# TC37XPD register map
Vendor: Infineon; Series: ATVMC; File version: 100
CPU: other r0p0, little endian, MPU, FPU, vendor SysTick, 4 interrupt priority bits
Registers are 32-bit, read-write, reset 0x0 unless marked. A register's access mark holds for its fields unless they carry their own. Offsets are from the block's base; [hi:lo] are bit positions; lines under a group give offsets from that group; {n}, {i} and the like mark numbered series; 'fields as' and 'values as' point back to an identical list.

## GTM (part 13 of 13)
Base 0xF0100000
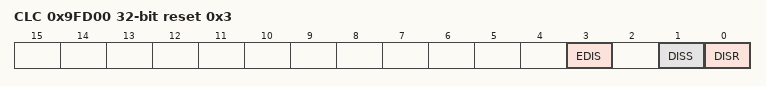
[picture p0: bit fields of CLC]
0x9FD00 CLC access per field reset 0x3 — Clock Control Register resetvalue={Application Reset:0x3}
  [3] EDIS rw — Sleep Mode Enable Control. Used for module s sleep mode control.
  [1] DISS ro — Module Disable Status Bit. This bit indicates the current status of the GTM module.
  [0] DISR rw — Module Disable Request Bit. Used for enable disable control of the GTM module.

## PMU
Base 0xF8038000
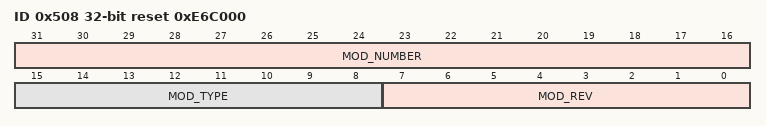
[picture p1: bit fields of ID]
0x508 ID ro reset 0xE6C000 (reset mask 0xFFFFFF00) — Module Identification Register resetvalue={Application Reset:0x0E6C000}
  [31:16] MOD_NUMBER — Module Number Value MOD NUMBER. This bit field defines the module identification number.
  [15:8] MOD_TYPE — Module Type MOD TYPE. This bit field is C0 H . It defines the module as a 32 bit module.
  [7:0] MOD_REV — Module Revision Number MOD REV. MOD REV defines the module revision number. See DMU Design Specification for MOD REV value.

## PFI0 — PFI
Base 0xA8080000
Same registers: PFI1 0xA8380000
0x00 ECCR ro — ECC Read Register resetvalue={System Reset:0x0}
  [21:0] RCODE — Error Correction Read Code RCODE. ECC code read from the Flash read buffer with last data read operation.
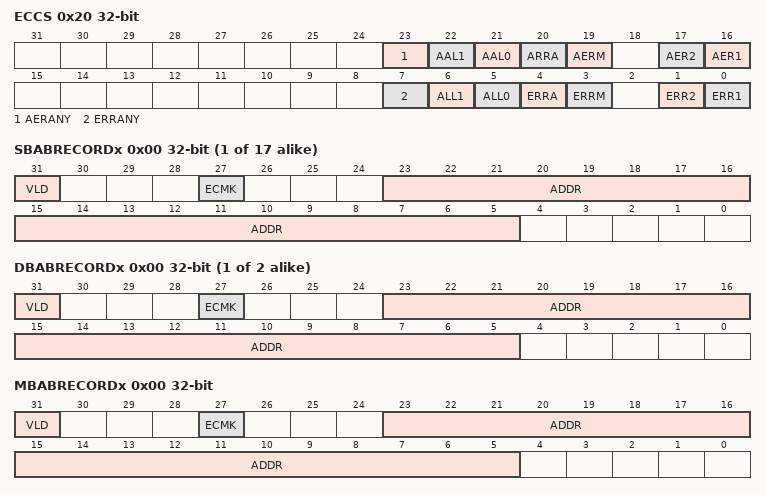
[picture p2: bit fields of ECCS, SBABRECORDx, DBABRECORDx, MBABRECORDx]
0x20 ECCS ro — ECC Status Register resetvalue={System Reset:0x0}
  [23] AERANY — Accumulated Any Read Access ECC Error AERANY. The status bit accumulates ECC failures during NVM read accesses.
  [22] AAL1 — Accumulated All Ones AAL1. The flag accumulates the All Ones condition during NVM read accesses.
  [21] AAL0 — Accumulated All Zeros AAL0. The flag accumulates the All Zeros condition during NVM read accesses.
  [20] ARRA — Accumulated ECC Error Within the Address ARRA. The flag accumulates an address errors during NVM read accesses.
  [19] AERM — Accumulated Multi bit ECC Errors AERM. The flag accumulates multi bit failures during NVM read accesses.
  [17] AER2 — Accumulated Double Bit ECC Errors AER2. The flag accumulates double bit failures during NVM read operations.
  [16] AER1 — Accumulated Single Bit ECC Errors AER1. The flag accumulates single bit failures during NVM read operations.
  [7] ERRANY — Any Read Access ECC Error ERRANY. The flag reports any ECC failure during the last NVM read access.
  [6] ALL1 — All Ones ALL1. The flag reports the All Ones condition during the last NVM read access.
  [5] ALL0 — Read Access All Zeros ALL0. The flag reports the All Zeros condition during the last NVM read access.
  [4] ERRA — Read Access ECC Error Within the Address ERRA. The flag reports an address error during the last NVM read access.
  [3] ERRM — Read Access Multi bit ECC Error ERRM. The flag reports multi bit ECC failure during the last NVM read access.
  [1] ERR2 — Read Access Double Bit ECC Error ERR2. The flag reports a double bit ECC failure during the last NVM read access.
  [0] ERR1 — Read Access Single Bit ECC Error ERR1. The flag reports a single bit ECC failure during the last NVM read access.
{0x2000+0x20*i} SBAB[{i}] (i=0..16) group
  0x00 SBABRECORDx ro — SBAB Record 0 resetvalue={System Reset:0x0}
    [31] VLD — Valid VLD
    [27] ECMK — Erase Counter Marker ECMK. The captured address is from the Flash or Erase Counter.
    [23:5] ADDR — Address ADDR. Captured local PFLASH bank address of the page with detected error.
{0x4000+0x20*i} DBAB[{i}] (i=0..1) group
  0x00 DBABRECORDx ro — DBAB Record 0 resetvalue={System Reset:0x0}
    [31] VLD — Valid VLD
    [27] ECMK — Erase Counter Marker ECMK. The captured address is from the Flash or Erase Counter.
    [23:5] ADDR — Address ADDR. Captured address of local PFLASH bank with detected error.
{0x8000+4i} MBAB[{i}] (i=0..0) group
  0x00 MBABRECORDx ro — MBAB Record 0 resetvalue={System Reset:0x0}
    fields as DBAB[0].DBABRECORDx
{0xC000+0x20*i} ZBAB[{i}] (i=0..3) group
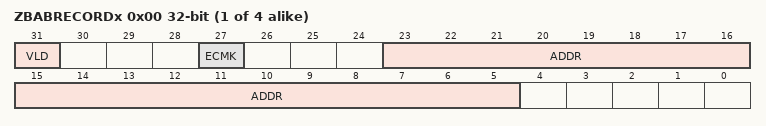
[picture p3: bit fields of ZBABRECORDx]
  0x00 ZBABRECORDx ro — ZBAB Record 0 resetvalue={System Reset:0x0}
    fields as DBAB[0].DBABRECORDx

## FSI
Base 0xF8030000
0x04 COMM_1 8-bit — Communication Register 1 resetvalue={System Reset:0x0}
  [7:0] COMM1 — FSI Communication 1 COMM1. This register can be written by FSI and DMU and is used to give status handshake information between FSI and DMU.
0x05 COMM_2 8-bit — Communication Register 2 resetvalue={System Reset:0x0}
  [7:0] COMM2 — FSI Communication 2 COMM2. This register can be written by FSI and DMU and is used to give status handshake information between FSI and DMU.
0x06 HSMCOMM_1 8-bit — HSM Communication Register 1 resetvalue={System Reset:0x0}
  [7:0] HSMCOMM1 — HSM FSI Communication 1 HSMCOMM1. This register can be written by FSI and DMU and is used to give status handshake information between FSI and DMU.
0x07 HSMCOMM_2 8-bit — HSM Communication Register 2 resetvalue={System Reset:0x0}
  [7:0] HSMCOMM2 — HSM FSI Communication 2 HSMCOMM2. This register can be written by FSI and DMU and is used to give status handshake information between FSI and DMU.
